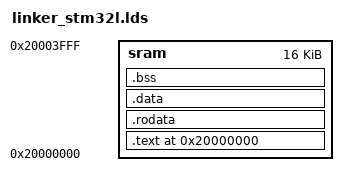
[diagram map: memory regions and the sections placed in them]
OUTPUT_FORMAT("elf32-littlearm")
ENTRY(_main)

MEMORY
{
	sram : ORIGIN = 0x20000000, LENGTH = 0x4000
}

SECTIONS
{
	.text(ORIGIN(sram)):
	{
		_main = .;
		_ftext = .;
		*(.text .stub .text.* .gnu.linkonce.t.*)
		_etext = .;
	} > sram

	.rodata :
	{
		. = ALIGN(4);
		_frodata = .;
		*(.rodata .rodata.* .gnu.linkonce.r.*)
		*(.rodata1)
		_erodata = .;
	} > sram

	.data :
	{
		. = ALIGN(4);
		_fdata = .;
		*(.data .data.* .gnu.linkonce.d.*)
		*(.data1)
		_gp = ALIGN(16);
		*(.sdata .sdata.* .gnu.linkonce.s.*)
		_edata = .;
	} > sram

	.bss :
	{
		. = ALIGN(4);
		_fbss = .;
		*(.dynsbss)
		*(.sbss .sbss.* .gnu.linkonce.sb.*)
		*(.scommon)
		*(.dynbss)
		*(.bss .bss.* .gnu.linkonce.b.*)
		*(COMMON)
		_ebss = .;
		_end = .;
	} > sram
}

PROVIDE(_fstack = ORIGIN(sram) + LENGTH(sram) - 4);
